# S32K324_M7 register map
Vendor: NXP Semiconductors; File version: 1.1
CPU: CM7 r0p1, little endian, MPU, FPU, VTOR, 4 interrupt priority bits
Registers are 32-bit, read-write, reset 0x0 unless marked. A register's access mark holds for its fields unless they carry their own. Offsets are from the block's base; [hi:lo] are bit positions; {n}, {i} and the like mark numbered series; 'fields as' and 'values as' point back to an identical list.

## DCM_GPR (part 2 of 2)
Base 0x402AC000; alternate view of DCM
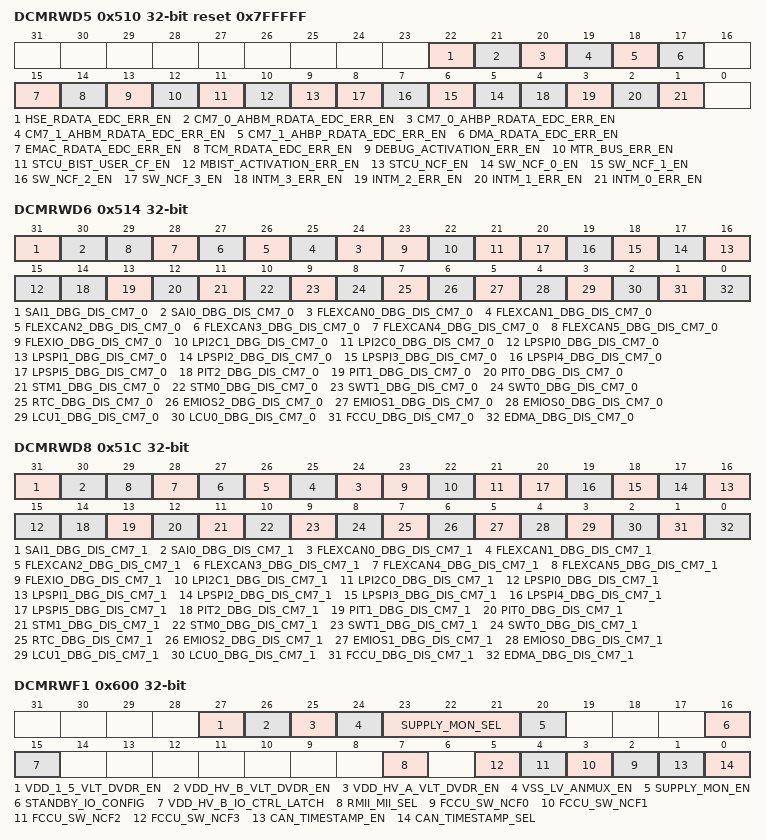
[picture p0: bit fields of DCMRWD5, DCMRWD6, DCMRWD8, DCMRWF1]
0x510 DCMRWD5 reset 0x7FFFFF — Read Write GPR On Destructive Reset Register
  [22] HSE_RDATA_EDC_ERR_EN — Enable bit for enabling the fault monitoring at FCCU NCF 1 for the fault: Integrity (EDC) error on HSE read data for safety
    0=No integrity error reported on HSE read data; 1=Integrity error reported on HSE read data
  [21] CM7_0_AHBM_RDATA_EDC_ERR_EN — Enable bit for enabling the fault monitoring at FCCU NCF 1 for the fault: Integrity error on CM7_0 main read data for safety
    0=No integrity error reported on CM7_0 main read data; 1=Integrity error reported on CM7_0 main read data
  [20] CM7_0_AHBP_RDATA_EDC_ERR_EN — Enable bit for enabling the fault monitoring at FCCU NCF 1 for the fault: Integrity error on CM7_0 peripheral read data for safety
    0=No integrity error reported on CM7_0 peripheral read data; 1=Integrity error reported on CM7_0 peripheral read data
  [19] CM7_1_AHBM_RDATA_EDC_ERR_EN — Enable bit for enabling the fault monitoring at FCCU NCF 1 for the fault: Integrity error on CM7_1 main read data for safety
    0=No integrity error reported on CM7_1 main read data; 1=Integrity error reported on CM7_1 main read data
  [18] CM7_1_AHBP_RDATA_EDC_ERR_EN — Enable bit for enabling the fault monitoring at FCCU NCF 1 for the fault: Integrity error on CM7_1 peripheral read data for safety
    0=No integrity error reported on CM7_1 peripheral read data; 1=Integrity error reported on CM7_1 peripheral read data
  [17] DMA_RDATA_EDC_ERR_EN — Enable bit for enabling the fault monitoring at FCCU NCF 1 for the fault: Integrity(EDC) error on eDMA read data for safety
    0=No integrity error reported on eDMA read data; 1=Integrity error reported on eDMA read data
  [15] EMAC_RDATA_EDC_ERR_EN — Enable bit for enabling the fault monitoring at FCCU NCF 1 for the fault: Integrity(EDC) error on EMAC read data for safety
    0=No integrity error reported on EMAC read data; 1=Integrity error reported on EMAC read data
  [14] TCM_RDATA_EDC_ERR_EN — Enable bit for enabling the fault monitoring at FCCU NCF 1 for the fault: Integrity(EDC) error on TCM read data for safety
    0=No integrity error reported on TCM read data; 1=Integrity error reported on TCM read data
  [13] DEBUG_ACTIVATION_ERR_EN — Enable bit for enabling the fault monitoring at FCCU NCF 5 for the fault: Monitoring of unintended debug activation
    0=Unintended debug not activated; 1=Unintended debug activated
  [12] MTR_BUS_ERR_EN — Enable bit for enabling the fault monitoring at FCCU NCF 5 for the fault: Fault reported due to illegal access on MTR
    0=No transfer error indicated from MTR; 1=Transfer error indicated from MTR
  [11] STCU_BIST_USER_CF_EN — Enable bit for enabling the fault monitoring at FCCU NCF 5 for the fault: L/M BIST enabled accidentally
    0=No accidental L/M BIST enabled; 1=Accidental L/M BIST enabled
  [10] MBIST_ACTIVATION_ERR_EN — Enable bit for enabling the fault monitoring at FCCU NCF 5 for the fault: Indicates an accidental backdoor access on memories
    0=No accidental backdoor enabled on memories; 1=Accidental backdoor enabled on memories
  [9] STCU_NCF_EN — Enable bit for enabling the fault monitoring at FCCU NCF 5 for the fault: STCU non-critical fault, that is, BIST result error
    0=STCU non-critical fault not reported; 1=STCU non-critical fault reported
  [n+5] SW_NCF_{n}_EN (n=0..3) — Enable bit for enabling the fault monitoring at FCCU NCF 7 for the fault: Software NCF{n}
    0=Software NCF{n}, DCMRWF1[FCCU_SW_NCF{n}] not enabled by software; 1=Software NCF{n}, DCMRWF1[FCCU_SW_NCF{n}] enabled by software
  [4] INTM_3_ERR_EN — Enable bit for enabling the fault monitoring at FCCU NCF 6 for the fault: Interrupt monitor3 error reported by error reported by INTM
    0=No error reported by interrupt monitor 3; 1=Error reported by interrupt monitor 3
  [3] INTM_2_ERR_EN — Enable bit for enabling the fault monitoring at FCCU NCF 6 for the fault: Interrupt monitor2 error reported by error reported by INTM
    0=No error reported by interrupt monitor 2; 1=Error reported by interrupt monitor 2
  [2] INTM_1_ERR_EN — Enable bit for enabling the fault monitoring at FCCU NCF 6 for the fault: Interrupt monitor1 error reported by error reported by INTM
    0=No error reported by interrupt monitor 1; 1=Error reported by interrupt monitor 1
  [1] INTM_0_ERR_EN — Enable bit for enabling the fault monitoring at FCCU NCF 6 for the fault: Interrupt monitor0 error reported by INTM
    0=No error reported by interrupt monitor 0; 1=Error reported by interrupt monitor 0
0x514 DCMRWD6 — Read Write GPR On Destructive Reset Register
  [31] SAI1_DBG_DIS_CM7_0 — SAI1 debug disable bit for CM7_0. Set this bit 1 to disable the debug of IP.
    0=SAI1 enters debug mode when CM7_0 enters debug mode; 1=SAI1 remains functional and is not impacted when CM7_0 enters debug mode
  [30] SAI0_DBG_DIS_CM7_0 — SAI0 debug disable bit for CM7_0. Set this bit 1 to disable the debug of IP.
    0=SAI0 enters debug mode when CM7_0 enters debug mode; 1=SAI0 remains functional and is not impacted when CM7_0 enters debug mode
  [n+24] FLEXCAN{n}_DBG_DIS_CM7_0 (n=0..5) — FLEXCAN{n} debug disable bit for CM7_0. Set this bit 1 to disable the debug of IP.
    0=FLEXCAN{n} enters debug mode when CM7_0 enters debug mode; 1=FLEXCAN{n} remains functional and is not impacted when CM7_0 enters debug mode
  [23] FLEXIO_DBG_DIS_CM7_0 — FLEXIO debug disable bit for CM7_0. Set this bit 1 to disable the debug of IP.
    0=FLEXIO enters debug mode when CM7_0 enters debug mode; 1=FLEXIO remains functional and is not impacted when CM7_0 enters debug mode
  [22] LPI2C1_DBG_DIS_CM7_0 — LPI2C1 debug disable bit for CM7_0. Set this bit 1 to disable the debug of IP.
    0=LPI2C1 enters debug mode when CM7_0 enters debug mode; 1=LPI2C1 remains functional and is not impacted when CM7_0 enters debug mode
  [21] LPI2C0_DBG_DIS_CM7_0 — LPI2C0 debug disable bit for CM7_0. Set this bit 1 to disable the debug of IP.
    0=LPI2C0 enters debug mode when CM7_0 enters debug mode; 1=LPI2C0 remains functional and is not impacted when CM7_0 enters debug mode
  [n+15] LPSPI{n}_DBG_DIS_CM7_0 (n=0..5) — LPSPI{n} debug disable bit for CM7_0. Set this bit 1 to disable the debug of IP.
    0=LPSPI{n} enters debug mode when CM7_0 enters debug mode; 1=LPSPI{n} remains functional and is not impacted when CM7_0 enters debug mode
  [14] PIT2_DBG_DIS_CM7_0 — PIT2 debug disable bit for CM7_0. Set this bit 1 to disable the debug of IP.
    0=PIT2 enters debug mode when CM7_0 enters debug mode; 1=PIT2 remains functional and is not impacted when CM7_0 enters debug mode
  [13] PIT1_DBG_DIS_CM7_0 — PIT1 debug disable bit for CM7_0. Set this bit 1 to disable the debug of IP.
    0=PIT1 enters debug mode when CM7_0 enters debug mode; 1=PIT1 remains functional and is not impacted when CM7_0 enters debug mode
  [12] PIT0_DBG_DIS_CM7_0 — PIT0 debug disable bit for CM7_0. Set this bit 1 to disable the debug of IP.
    0=PIT0 enters debug mode when CM7_0 enters debug mode; 1=PIT0 remains functional and is not impacted when CM7_0 enters debug mode
  [11] STM1_DBG_DIS_CM7_0 — STM1 debug disable bit for CM7_0. Set this bit 1 to disable the debug of IP.
    0=STM1 enters debug mode when CM7_0 enters debug mode; 1=STM1 remains functional and is not impacted when CM7_0 enters debug mode
  [10] STM0_DBG_DIS_CM7_0 — STM0 debug disable bit for CM7_0. Set this bit 1 to disable the debug of IP.
    0=STM0 enters debug mode when CM7_0 enters debug mode; 1=STM0 remains functional and is not impacted when CM7_0 enters debug mode
  [9] SWT1_DBG_DIS_CM7_0 — SWT1 debug disable bit for CM7_0. Set this bit 1 to disable the debug of IP.
    0=SWT0 enters debug mode when CM7_0 enters debug mode; 1=SWT0 remains functional and is not impacted when CM7_0 enters debug mode
  [8] SWT0_DBG_DIS_CM7_0 — SWT0 debug disable bit for CM7_0. Set this bit 1 to disable the debug of IP.
    values as SWT1_DBG_DIS_CM7_0
  [7] RTC_DBG_DIS_CM7_0 — RTC debug disable bit for CM7_0. Set this bit 1 to disable the debug of IP.
    0=RTC enters debug mode when CM7_0 enters debug mode; 1=RTC remains functional and is not impacted when CM7_0 enters debug mode
  [6] EMIOS2_DBG_DIS_CM7_0 — EMIOS2 debug disable bit for CM7_0. Set this bit 1 to disable the debug of IP.
    0=eMIOS2 enters debug mode when CM7_0 enters debug mode; 1=eMIOS2 remains functional and is not impacted when CM7_0 enters debug mode
  [5] EMIOS1_DBG_DIS_CM7_0 — EMIOS1 debug disable bit for CM7_0. Set this bit 1 to disable the debug of IP.
    0=eMIOS1 enters debug mode when CM7_0 enters debug mode; 1=eMIOS1 remains functional and is not impacted when CM7_0 enters debug mode
  [4] EMIOS0_DBG_DIS_CM7_0 — EMIOS0 debug disable bit for CM7_0. Set this bit 1 to disable the debug of IP.
    0=eMIOS0 enters debug mode when CM7_0 enters debug mode; 1=eMIOS0 remains functional and is not impacted when CM7_0 enters debug mode
  [3] LCU1_DBG_DIS_CM7_0 — LCU1 debug disable bit for CM7_0. Set this bit 1 to disable the debug of IP.
    0=LCU1 enters debug mode when CM7_0 enters debug mode; 1=LCU1 remains functional and is not impacted when CM7_0 enters debug mode
  [2] LCU0_DBG_DIS_CM7_0 — LCU0 debug disable bit for CM7_0. Set this bit 1 to disable the debug of IP.
    0=LCU0 enters debug mode when CM7_0 enters debug mode; 1=LCU0 remains functional and is not impacted when CM7_0 enters debug mode
  [1] FCCU_DBG_DIS_CM7_0 — FCCU debug disable bit for CM7_0. Set this bit 1 to disable the debug of IP.
    0=FCCU enters debug mode when CM7_0 enters debug mode; 1=FCCU remains functional and is not impacted when CM7_0 enters debug mode
  [0] EDMA_DBG_DIS_CM7_0 — EDMA debug disable bit for CM7_0. Set this bit 1 to disable the debug of IP.
    0=EDMA enters debug mode when CM7_0 enters debug mode; 1=EDMA remains functional and is not impacted when CM7_0 enters debug mode
0x518 DCMRWD7 — Read Write GPR On Destructive Reset Register
0x51C DCMRWD8 — Read Write GPR On Destructive Reset Register
  [31] SAI1_DBG_DIS_CM7_1 — SAI1 debug disable bit for CM7_1. Set this bit 1 to disable the debug of IP.
    0=SAI1 enters debug mode when CM7_1 enters debug mode; 1=SAI1 remains functional and is not impacted when CM7_1 enters debug mode
  [30] SAI0_DBG_DIS_CM7_1 — SAI0 debug disable bit for CM7_1. Set this bit 1 to disable the debug of IP.
    0=SAI0 enters debug mode when CM7_1 enters debug mode; 1=SAI0 remains functional and is not impacted when CM7_1 enters debug mode
  [n+24] FLEXCAN{n}_DBG_DIS_CM7_1 (n=0..5) — FLEXCAN{n} debug disable bit for CM7_1. Set this bit 1 to disable the debug of IP.
    0=FLEXCAN{n} enters debug mode when CM7_1 enters debug mode; 1=FLEXCAN{n} remains functional and is not impacted when CM7_1 enters debug mode
  [23] FLEXIO_DBG_DIS_CM7_1 — FLEXIO debug disable bit for CM7_1. Set this bit 1 to disable the debug of IP.
    0=FLEXIO enters debug mode when CM7_1 enters debug mode; 1=FLEXIO remains functional and is not impacted when CM7_1 enters debug mode
  [22] LPI2C1_DBG_DIS_CM7_1 — LPI2C1 debug disable bit for CM7_1. Set this bit 1 to disable the debug of IP.
    0=LPI2C1 enters debug mode when CM7_1 enters debug mode; 1=LPI2C1 remains functional and is not impacted when CM7_1 enters debug mode
  [21] LPI2C0_DBG_DIS_CM7_1 — LPI2C0 debug disable bit for CM7_1. Set this bit 1 to disable the debug of IP.
    0=LPI2C0 enters debug mode when CM7_1 enters debug mode; 1=LPI2C0 remains functional and is not impacted when CM7_1 enters debug mode
  [n+15] LPSPI{n}_DBG_DIS_CM7_1 (n=0..5) — LPSPI{n} debug disable bit for CM7_1. Set this bit 1 to disable the debug of IP.
    0=LPSPI{n} enters debug mode when CM7_1 enters debug mode; 1=LPSPI{n} remains functional and is not impacted when CM7_1 enters debug mode
  [14] PIT2_DBG_DIS_CM7_1 — PIT2 debug disable bit for CM7_1. Set this bit 1 to disable the debug of IP.
    0=PIT2 enters debug mode when CM7_1 enters debug mode; 1=PIT2 remains functional and is not impacted when CM7_1 enters debug mode
  [13] PIT1_DBG_DIS_CM7_1 — PIT1 debug disable bit for CM7_1. Set this bit 1 to disable the debug of IP.
    0=PIT1 enters debug mode when CM7_1 enters debug mode; 1=PIT1 remains functional and is not impacted when CM7_1 enters debug mode
  [12] PIT0_DBG_DIS_CM7_1 — PIT0 debug disable bit for CM7_1. Set this bit 1 to disable the debug of IP.
    0=PIT0 enters debug mode when CM7_1 enters debug mode; 1=PIT0 remains functional and is not impacted when CM7_1 enters debug mode
  [11] STM1_DBG_DIS_CM7_1 — STM1 debug disable bit for CM7_1. Set this bit 1 to disable the debug of IP.
    0=STM1 enters debug mode when CM7_1 enters debug mode; 1=STM1 remains functional and is not impacted when CM7_1 enters debug mode
  [10] STM0_DBG_DIS_CM7_1 — STM0 debug disable bit for CM7_1. Set this bit 1 to disable the debug of IP.
    0=STM0 enters debug mode when CM7_1 enters debug mode; 1=STM0 remains functional and is not impacted when CM7_1 enters debug mode
  [9] SWT1_DBG_DIS_CM7_1 — SWT1 debug disable bit for CM7_1. Set this bit 1 to disable the debug of IP.
    0=SWT1 enters debug mode when CM7_1 enters debug mode; 1=SWT1 remains functional and is not impacted when CM7_1 enters debug mode
  [8] SWT0_DBG_DIS_CM7_1 — SWT0 debug disable bit for CM7_1. Set this bit 1 to disable the debug of IP.
    0=SWT0 enters debug mode when CM7_1 enters debug mode; 1=SWT0 remains functional and is not impacted when CM7_1 enters debug mode
  [7] RTC_DBG_DIS_CM7_1 — RTC debug disable bit for CM7_1. Set this bit 1 to disable the debug of IP.
    0=RTC enters debug mode when CM7_1 enters debug mode; 1=RTC remains functional and is not impacted when CM7_1 enters debug mode
  [6] EMIOS2_DBG_DIS_CM7_1 — EMIOS2 debug disable bit for CM7_1. Set this bit 1 to disable the debug of IP.
    0=EMIOS2 enters debug mode when CM7_1 enters debug mode; 1=EMIOS2 remains functional and is not impacted when CM7_1 enters debug mode
  [5] EMIOS1_DBG_DIS_CM7_1 — EMIOS1 debug disable bit for CM7_1. Set this bit 1 to disable the debug of IP.
    0=EMIOS1 enters debug mode when CM7_1 enters debug mode; 1=EMIOS1 remains functional and is not impacted when CM7_1 enters debug mode
  [4] EMIOS0_DBG_DIS_CM7_1 — EMIOS0 debug disable bit for CM7_1. Set this bit 1 to disable the debug of IP.
    0=EMIOS0 enters debug mode when CM7_1 enters debug mode; 1=EMIOS0 remains functional and is not impacted when CM7_1 enters debug mode
  [3] LCU1_DBG_DIS_CM7_1 — LCU1 debug disable bit for CM7_1. Set this bit 1 to disable the debug of IP.
    0=LCU1 enters debug mode when CM7_1 enters debug mode; 1=LCU1 remains functional and is not impacted when CM7_1 enters debug mode
  [2] LCU0_DBG_DIS_CM7_1 — LCU0 debug disable bit for CM7_1. Set this bit 1 to disable the debug of IP.
    0=LCU0 enters debug mode when CM7_1 enters debug mode; 1=LCU0 remains functional and is not impacted when CM7_1 enters debug mode
  [1] FCCU_DBG_DIS_CM7_1 — FCCU debug disable bit for CM7_1. Set this bit 1 to disable the debug of IP.
    0=FCCU enters debug mode when CM7_1 enters debug mode; 1=FCCU remains functional and is not impacted when CM7_1 enters debug mode
  [0] EDMA_DBG_DIS_CM7_1 — EDMA debug disable bit for CM7_1. Set this bit 1 to disable the debug of IP.
    0=EDMA enters debug mode when CM7_1 enters debug mode; 1=EDMA remains functional and is not impacted when CM7_1 enters debug mode
0x520 DCMRWD9 — Read Write GPR On Destructive Reset Register
0x600 DCMRWF1 — Read Write GPR On Functional Reset Register
  [27] VDD_1_5_VLT_DVDR_EN — Enable for VDD1P5 2:1 divider for voltage measurement using supply voltage monitoring by ADC.
    0=Disabled; 1=Enabled
  [26] VDD_HV_B_VLT_DVDR_EN — Enable for VDD_HV_B 2:1 divider for voltage measurement using supply voltage monitoring by ADC.
    0=Disabled; 1=Enabled
  [25] VDD_HV_A_VLT_DVDR_EN — Enable for VDD_HV_A 2:1 divider for voltage measurement using supply voltage monitoring by ADC.
    0=Disabled; 1=Enabled
  [24] VSS_LV_ANMUX_EN — Enable VSS_LV monitoring
    0=Disabled; 1=Enabled
  [23:21] SUPPLY_MON_SEL — Selects the source of voltage used by ADC for supply monitoring
    0=VDD_HV_A_DIV; 1=VDD_HV_B_DIV; 2=VDD_1.5_DIV; 3=VDD_2.5_OSC; 4=VDD1.1_PD1_HOT_POINT; 5=VDD1.1_PD1_COLD_POINT; 6=VDD1.1_PLL; 7=VDD1.1_PD0
  [20] SUPPLY_MON_EN — Enable the supply voltage monitoring by ADC.
    0=Disabled; 1=Enabled
  [16] STANDBY_IO_CONFIG — Controls the IO state in the standby mode.
    0=STANDBY IO configuration standby entry: Must be written as 0 before IO configurations are done in standby entry sequence; 1=STANDBY IO configuration standby exit: Must be written as 1 after IO configurations are done on standby exit
  [15] VDD_HV_B_IO_CTRL_LATCH — Controls the IO controls latching in low frequency RUN mode to reduce power consumption on VDD_HV_B domain pins.
    0=VDD_HV_B domain pins function as normal; 1=The IO controls of VDD_HV_B domain pins are latched
  [7] RMII_MII_SEL — Selects between MII and RMII mode of ethernet.
    0=MII mode; 1=RMII mode
  [n+2] FCCU_SW_NCF{n} (n=0..3) — Control to initiate Software NCF to FCCU.
    0=NCF to FCCU will not be generated; 1=NCF to FCCU will be generated. For exact slot of FCCU, please refer FCCU chapter.
  [1] CAN_TIMESTAMP_EN — Enables CAN timestamping feature for all flexcans.
    0=CAN timestamping is disabled; 1=CAN timestamping is enabled
  [0] CAN_TIMESTAMP_SEL — Select between EMAC and STM for CAN timestamping
    0=EMAC selected for CAN timestamping; 1=STM0 selected for CAN timestamping
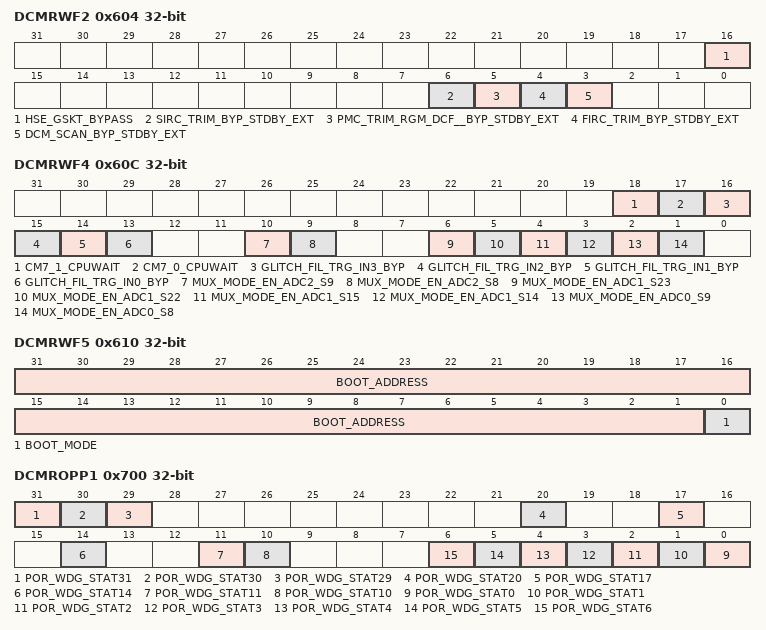
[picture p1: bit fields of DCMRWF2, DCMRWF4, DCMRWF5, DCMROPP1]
0x604 DCMRWF2 — Read Write GPR On Functional Reset Register
  [16] HSE_GSKT_BYPASS — Control to enable the HSE IAHB gasket behavior out of standby mode.
    0=When configured as 0, HSE IAHB gasket bypass configuration is controlled by DCF client; 1=When configured as 1, HSE IAHB gasket is bypassed out of standby
  [6] SIRC_TRIM_BYP_STDBY_EXT — Control to bypass the SIRC trimming on standby exit.
    0=Not bypassed; 1=Bypassed
  [5] PMC_TRIM_RGM_DCF__BYP_STDBY_EXT — Control to bypass the PMC trimming and RGM DCF loading on standby exit.
    0=Not bypassed; 1=Bypassed
  [4] FIRC_TRIM_BYP_STDBY_EXT — Control to bypass the FIRC trimming on standby exit.
    0=Not bypassed; 1=Bypassed
  [3] DCM_SCAN_BYP_STDBY_EXT — Control to bypass the DCM scanning on standby exit.
    0=Not bypassed; 1=Bypassed
0x60C DCMRWF4 — Read Write GPR On Functional Reset Register
  [18] CM7_1_CPUWAIT — Configuration to put CM7_1 core into wait mode
    0=CPUWAIT for CM7_1 disabled; 1=CM7_1 put into wait mode using CPUWAIT
  [17] CM7_0_CPUWAIT — Configuration to put CM7_0 core into wait mode.
    0=CPUWAIT for CM7_0 disabled; 1=CM7_0 put into wait mode using CPUWAIT
  [16] GLITCH_FIL_TRG_IN3_BYP — Selects whether to BYPASS or filter out the pulse.
    0=Glitch filter on TRGMUX input60 is enabled; 1=Glitch filter on TRGMUX input60 is bypassed
  [15] GLITCH_FIL_TRG_IN2_BYP — Selects whether to BYPASS or filter out the pulse.
    0=Glitch filter on TRGMUX input61 is enabled; 1=Glitch filter on TRGMUX input61 is bypassed
  [14] GLITCH_FIL_TRG_IN1_BYP — Selects whether to BYPASS or filter out the pulse.
    0=Glitch filter on TRGMUX input62 is enabled; 1=Glitch filter on TRGMUX input62 is bypassed
  [13] GLITCH_FIL_TRG_IN0_BYP — Selects whether to BYPASS or filter out the pulse.
    0=Glitch filter on TRGMUX input63 is enabled; 1=Glitch filter on TRGMUX input63 is bypassed
  [10] MUX_MODE_EN_ADC2_S9 — Selects the GPIO46 to drive adc2 standard channel 9th.
    0=Selects the default PAD 1; 1=Selects the PAD mentioned in description
  [9] MUX_MODE_EN_ADC2_S8 — Selects the GPIO45 to drive adc2 standard channel 8th.
    values as MUX_MODE_EN_ADC2_S9
  [6] MUX_MODE_EN_ADC1_S23 — Selects the GPIO115 to drive ADC1 standard channel 23rd.
    values as MUX_MODE_EN_ADC2_S9
  [5] MUX_MODE_EN_ADC1_S22 — Selects the GPIO114 to drive ADC1 standard channel 22nd.
    values as MUX_MODE_EN_ADC2_S9
  [4] MUX_MODE_EN_ADC1_S15 — Selects the GPIO33 to drive ADC1 standard channel 15th.
    values as MUX_MODE_EN_ADC2_S9
  [3] MUX_MODE_EN_ADC1_S14 — Selects the GPIO32 to drive ADC1 standard channel 14th.
    values as MUX_MODE_EN_ADC2_S9
  [2] MUX_MODE_EN_ADC0_S9 — Selects the GPIO46 to drive ADC0 standard channel 9th.
    values as MUX_MODE_EN_ADC2_S9
  [1] MUX_MODE_EN_ADC0_S8 — Selects the GPIO45 to drive ADC0 standard channel 8th.
    values as MUX_MODE_EN_ADC2_S9
0x610 DCMRWF5 reset not defined — Read Write GPR On Functional Reset Register
  [31:1] BOOT_ADDRESS — Cortex-M7_0 base address of vector table to be used after exiting Standby mode (only to be considered in Fast Standby mode
  [0] BOOT_MODE — Selects the boot mode after exiting Standby mode.
    0=Normal; 1=Fast Standby
0x700 DCMROPP1 write-1-clears — Read Only GPR On PMCPOR Reset
  [31] POR_WDG_STAT31 write-1-clears — This bit captures MC_RGM reset event (if occured) while the device is in STANDBY mode.
    0=MC_RGM reset event not detected or no reset event arrived in STANDBY mode when POR_WDG overflows; 1=MC_RGM reset event is detected in STANDBY mode when POR_WDG overflows
  [30] POR_WDG_STAT30 write-1-clears — This bit captures the status of standby exit acknowledgement by MC_PCU when POR_WDG overflows.
    0=MC_PCU has not acknowledged standby exit when POR_WDG overflows; 1=MC_PCU has acknowledged standby exit when POR_WDG overflows
  [29] POR_WDG_STAT29 write-1-clears — This bit captures the status of standby entry request initiated by MC_ME when POR_WDG overflows.
    0=MC_ME standby request is active when POR_WDG overflows; 1=MC_ME standby request is not active when POR_WDG overflows
  [20] POR_WDG_STAT20 write-1-clears — This bit captures the status of functional reset sequence process DEST0 when POR_WDG overflows.
    0=DEST0 is inactive when POR_WDG overflows; 1=DEST0 is active when POR_WDG overflows
  [17] POR_WDG_STAT17 write-1-clears — This bit captures the status of functional reset sequence process FUNC10 when POR_WDG overflows.
    0=FUNC10 is inactive when POR_WDG overflows; 1=FUNC10 is active when POR_WDG overflows
  [14] POR_WDG_STAT14 write-1-clears — This bit captures the status of functional reset sequence process FUNC9 when POR_WDG overflows.
    0=FUNC9 is inactive when POR_WDG overflows; 1=FUNC9 is active when POR_WDG overflows
  [11] POR_WDG_STAT11 write-1-clears — This bit captures the status of functional reset sequence process FUNC7 when POR_WDG overflows.
    0=FUNC8 is inactive when POR_WDG overflows; 1=FUNC8 is active when POR_WDG overflows
  [10] POR_WDG_STAT10 write-1-clears — This bit captures the status of functional reset sequence process FUNC7 when POR_WDG overflows.
    0=FUNC7 is inactive when POR_WDG overflows; 1=FUNC7 is active when POR_WDG overflows
  [n] POR_WDG_STAT{n} write-1-clears (n=0..6) — This bit captures the status of functional reset sequence process FUNC{n} when POR_WDG overflows.
    0=FUNC{n} is inactive when POR_WDG overflows; 1=FUNC{n} is active when POR_WDG overflows
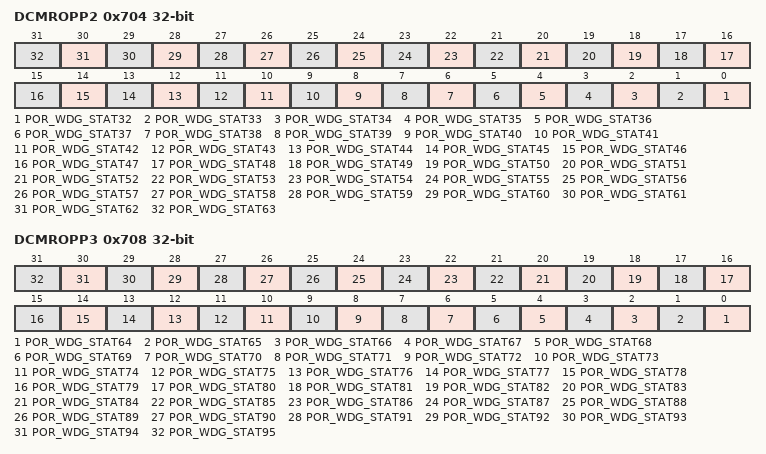
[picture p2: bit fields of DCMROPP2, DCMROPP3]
0x704 DCMROPP2 write-1-clears — Read Only GPR On PMCPOR Reset
  [n-32] POR_WDG_STAT{n} write-1-clears (n=32..63) — This bit captures MC_RGM functional/external event status register when POR_WDG overflows.
    0=MC_RGM.RGM_FES[{n-32}] is 0 when POR_WDG overflows; 1=MC_RGM.RGM_FES[{n-32}] is 1 when POR_WDG overflows
0x708 DCMROPP3 write-1-clears — Read Only GPR On PMCPOR Reset
  [n-64] POR_WDG_STAT{n} write-1-clears (n=64..95) — This bit captures MC_RGM destructive event status register when POR_WDG overflows.
    0=MC_RGM.RGM_DES[{n-64}] is 0 when POR_WDG overflows; 1=MC_RGM.RGM_DES[{n-64}] is 1 when POR_WDG overflows
0x70C DCMROPP4 write-1-clears — Read Only GPR On PMCPOR Reset
  [0] POR_WDG_STAT96 write-1-clears — This bit captures POR_WDG reset event if POR_WDG initiates a POR sequence.
    0=POR_WDG is inactive; 1=POR_WDG has detected a stuck scenario and raised device POR event. Refer POR_WDG_STAT[95:0] for device status when POR_WDG overflows
